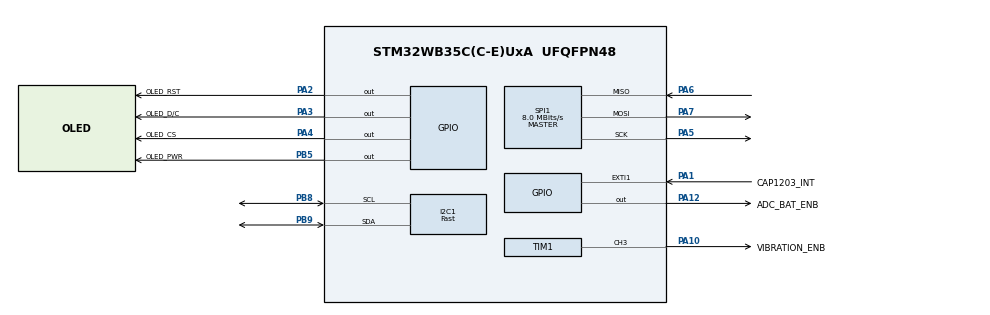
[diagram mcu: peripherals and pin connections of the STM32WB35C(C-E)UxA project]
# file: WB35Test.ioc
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I2C1.I2C_Speed_Mode=I2C_Fast
I2C1.Timing=0x00300F38
Mcu.Family=STM32WB
Mcu.Name=STM32WB35C(C-E)UxA
Mcu.Package=UFQFPN48
NVIC.EXTI1_IRQn=true\:0\:0\:false\:false\:true\:true\:true
NVIC.HSEM_IRQn=true\:0\:0\:false\:false\:true\:false\:true
NVIC.IPCC_C1_RX_IRQn=true\:0\:0\:false\:false\:true\:true\:true
NVIC.IPCC_C1_TX_IRQn=true\:0\:0\:false\:false\:true\:true\:true
NVIC.PriorityGroup=NVIC_PRIORITYGROUP_4
NVIC.RTC_WKUP_IRQn=true\:0\:0\:false\:false\:true\:true\:true
NVIC.TIM1_UP_TIM16_IRQn=true\:0\:0\:false\:false\:true\:true\:true
OSC_IN.Mode=HSE-External-Oscillator
OSC_IN.Signal=RCC_OSC_IN
OSC_OUT.Mode=HSE-External-Oscillator
OSC_OUT.Signal=RCC_OSC_OUT
PA0.Mode=SYS_WakeUp0
PA0.Signal=SYS_WKUP1
PA1.GPIO_Label=CAP1203_INT
PA1.Signal=GPXTI1
PA10.GPIO_Label=VIBRATION_ENB
PA10.Signal=S_TIM1_CH3
PA12.GPIO_Label=ADC_BAT_ENB
PA12.PinState=GPIO_PIN_SET
PA12.Signal=GPIO_Output
PA2.GPIO_Label=OLED_RST
PA2.Signal=GPIO_Output
PA3.GPIO_Label=OLED_D/C
PA3.Signal=GPIO_Output
PA4.GPIO_Label=OLED_CS
PA4.PinState=GPIO_PIN_SET
PA4.Signal=GPIO_Output
PA5.Mode=Full_Duplex_Master
PA5.Signal=SPI1_SCK
PA6.Mode=Full_Duplex_Master
PA6.Signal=SPI1_MISO
PA7.Mode=Full_Duplex_Master
PA7.Signal=SPI1_MOSI
PB5.GPIO_Label=OLED_PWR
PB5.Signal=GPIO_Output
PB8.Mode=I2C
PB8.Signal=I2C1_SCL
PB9.Mode=I2C
PB9.Signal=I2C1_SDA
PC14-OSC32_IN.Mode=LSE-External-Oscillator
PC14-OSC32_IN.Signal=RCC_OSC32_IN
PC15-OSC32_OUT.Mode=LSE-External-Oscillator
PC15-OSC32_OUT.Signal=RCC_OSC32_OUT
ProjectManager.HeapSize=0x200
ProjectManager.StackSize=0x400
ProjectManager.TargetToolchain=MDK-ARM V5.32
RCC.ADCFreq_Value=128000000
RCC.AHBFreq_Value=32000000
RCC.APB1Freq_Value=32000000
RCC.APB1TimFreq_Value=32000000
RCC.APB2Freq_Value=32000000
RCC.APB2TimFreq_Value=32000000
RCC.APB3Freq_Value=16000000
RCC.CodegenConfigPeriph=true
RCC.CortexFreq_Value=32000000
RCC.HCLKFreq_Value=32000000
RCC.HSE_VALUE=32000000
RCC.HSI48_VALUE=48000000
RCC.HSI_VALUE=16000000
RCC.LSE_Timout=5000
RCC.MSIClockRange=RCC_MSIRANGE_10
RCC.RFWKPClockSelection=RCC_RFWKPCLKSOURCE_LSE
RCC.RTCClockSelection=RCC_RTCCLKSOURCE_LSE
RCC.SYSCLKFreq_VALUE=32000000
RCC.USBFreq_Value=128000000
RCC.VCOOutputFreq_Value=256000000
RF1.Mode=RF1_Activate
RF1.Signal=RF_RF1
SH.S_TIM1_CH3.0=TIM1_CH3,PWM Generation3 CH3
SPI1.BaudRatePrescaler=SPI_BAUDRATEPRESCALER_4
SPI1.CalculateBaudRate=8.0 MBits/s
SPI1.DataSize=SPI_DATASIZE_8BIT
SPI1.Direction=SPI_DIRECTION_2LINES
SPI1.Mode=SPI_MODE_MASTER
SPI1.VirtualType=VM_MASTER
STM32_WPAN.AD_TYPE_COMPLETE_LOCAL_NAME=SMRT_GLASS
STM32_WPAN.AD_TYPE_COMPLETE_LOCAL_NAME_LENGTH=11
STM32_WPAN.CUSTOM_P2P_SERVER=Disabled
STM32_WPAN.CUSTOM_TEMPLATE=Enabled
STM32_WPAN.GAP_PERIPHERAL_ROLE=0
STM32_WPAN.INCLUDE_AD_TYPE_COMPLETE_LOCAL_NAME=1
STM32_WPAN.LOCAL_NAME=MY_GLAS
STM32_WPAN.LOCAL_NAME_FORMATTED=,'M','Y','_','G','L','A','S'
STM32_WPAN.NUMBER_OF_SERVICES=2
STM32_WPAN.SERVICE1_CHAR1_GATT_NOTIFY_ATTRIBUTE_WRITE=\ 
STM32_WPAN.SERVICE1_CHAR1_GATT_NOTIFY_READ_REQ_AND_WAIT_FOR_APPL_RESP=\ 
STM32_WPAN.SERVICE1_CHAR1_GATT_NOTIFY_WRITE_REQ_AND_WAIT_FOR_APPL_RESP=\ 
STM32_WPAN.SERVICE1_CHAR1_LONG_NAME=DVC_FW_NR
STM32_WPAN.SERVICE1_CHAR1_PROP_READ=CHAR_PROP_READ
STM32_WPAN.SERVICE1_CHAR1_SHORT_NAME=DVC_FW_NR
STM32_WPAN.SERVICE1_CHAR1_UUID=00 11
STM32_WPAN.SERVICE1_CHAR1_VALUE_LENGTH=4
STM32_WPAN.SERVICE1_CHAR2_GATT_NOTIFY_ATTRIBUTE_WRITE=\ 
STM32_WPAN.SERVICE1_CHAR2_GATT_NOTIFY_READ_REQ_AND_WAIT_FOR_APPL_RESP=\ 
STM32_WPAN.SERVICE1_CHAR2_GATT_NOTIFY_WRITE_REQ_AND_WAIT_FOR_APPL_RESP=\ 
STM32_WPAN.SERVICE1_CHAR2_LENGTH_CHARACTERISTIC=CHAR_VALUE_LEN_VARIABLE
STM32_WPAN.SERVICE1_CHAR2_LONG_NAME=DVC_NAME
STM32_WPAN.SERVICE1_CHAR2_PROP_READ=CHAR_PROP_READ
STM32_WPAN.SERVICE1_CHAR2_SHORT_NAME=DVC_NAME
STM32_WPAN.SERVICE1_CHAR2_UUID=00 12
STM32_WPAN.SERVICE1_CHAR2_VALUE_LENGTH=32
STM32_WPAN.SERVICE1_LONG_NAME=DVC_INFO_SVC
STM32_WPAN.SERVICE1_NUMBER_OF_CHARACTERISTICS=2
STM32_WPAN.SERVICE1_SHORT_NAME=DVC_INFO_SVC
STM32_WPAN.SERVICE1_UUID=00 10
STM32_WPAN.SERVICE2_CHAR1_LENGTH_CHARACTERISTIC=CHAR_VALUE_LEN_VARIABLE
STM32_WPAN.SERVICE2_CHAR1_LONG_NAME=TIME_UPDATE
STM32_WPAN.SERVICE2_CHAR1_PROP_WRITE_WITHOUT_RESP=CHAR_PROP_WRITE_WITHOUT_RESP
STM32_WPAN.SERVICE2_CHAR1_SHORT_NAME=TIME_UPDATE
STM32_WPAN.SERVICE2_CHAR1_UUID=00 21
STM32_WPAN.SERVICE2_CHAR1_VALUE_LENGTH=32
STM32_WPAN.SERVICE2_CHAR2_GATT_NOTIFY_READ_REQ_AND_WAIT_FOR_APPL_RESP=GATT_NOTIFY_READ_REQ_AND_WAIT_FOR_APPL_RESP
STM32_WPAN.SERVICE2_CHAR2_GATT_NOTIFY_WRITE_REQ_AND_WAIT_FOR_APPL_RESP=GATT_NOTIFY_WRITE_REQ_AND_WAIT_FOR_APPL_RESP
STM32_WPAN.SERVICE2_CHAR2_LENGTH_CHARACTERISTIC=CHAR_VALUE_LEN_VARIABLE
STM32_WPAN.SERVICE2_CHAR2_LONG_NAME=PUSH_NOTIFICATION
STM32_WPAN.SERVICE2_CHAR2_PROP_WRITE_WITHOUT_RESP=CHAR_PROP_WRITE_WITHOUT_RESP
STM32_WPAN.SERVICE2_CHAR2_SHORT_NAME=PUSH_NOTIFICATION
STM32_WPAN.SERVICE2_CHAR2_UUID=00 22
STM32_WPAN.SERVICE2_CHAR2_VALUE_LENGTH=128
STM32_WPAN.SERVICE2_LONG_NAME=RECEIVE_SVC
STM32_WPAN.SERVICE2_NUMBER_OF_CHARACTERISTICS=2
STM32_WPAN.SERVICE2_SHORT_NAME=RECEIVE_SVC
STM32_WPAN.SERVICE2_UUID=00 20
TIM1.Channel-PWM\ Generation3\ CH3=TIM_CHANNEL_3
TIM1.Period=99
TIM1.Prescaler=3
TIM1.TIM_MasterOutputTrigger=TIM_TRGO_UPDATE
TIM1.TIM_MasterOutputTrigger2=TIM_TRGO2_UPDATE
VP_HSEM_VS_HSEM.Mode=HSEM_Activate
VP_IPCC_VS_IPCC.Mode=IPCC_Activate
VP_RTC_VS_RTC_Activate.Mode=RTC_Enabled
VP_RTC_VS_RTC_WakeUp_intern.Mode=WakeUp
VP_SEQUENCER_VS_SEQUENCER.Mode=SEQUENCER_Enabled
VP_STM32_WPAN_VS_BLE_HOST.Mode=STM32_WPAN_Enabled
VP_TIM1_VS_ClockSourceINT.Mode=Internal
VP_TINY_LPM_VS_TINY_LPM.Mode=TINY_LPM_Enabled
board=custom

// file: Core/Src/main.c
/* USER CODE BEGIN Header */
/**
  ******************************************************************************
  * @file           : main.c
  * @brief          : Main program body
  ******************************************************************************
  * @attention
  *
  * Copyright (c) 2022 STMicroelectronics.
  * All rights reserved.
  *
  * This software is licensed under terms that can be found in the LICENSE file
  * in the root directory of this software component.
  * If no LICENSE file comes with this software, it is provided AS-IS.
  *
  ******************************************************************************
  */
/* USER CODE END Header */
#include "main.h"

/* USER CODE BEGIN Includes */
#include "glasses_app.h"
#include "glasses_ota.h"
#include "app_ble.h"
/* USER CODE END Includes */

I2C_HandleTypeDef hi2c1;

IPCC_HandleTypeDef hipcc;

RTC_HandleTypeDef hrtc;

SPI_HandleTypeDef hspi1;

TIM_HandleTypeDef htim1;

void SystemClock_Config(void);
void PeriphCommonClock_Config(void);
static void MX_IPCC_Init(void);
static void MX_GPIO_Init(void);
static void MX_RTC_Init(void);
static void MX_RF_Init(void);
static void MX_I2C1_Init(void);
static void MX_SPI1_Init(void);
static void MX_TIM1_Init(void);

int main(void)
{

  /* MCU Configuration--------------------------------------------------------*/

  /* Reset of all peripherals, Initializes the Flash interface and the Systick. */
  HAL_Init();
  /* Config code for STM32_WPAN (HSE Tuning must be done before system clock configuration) */
  MX_APPE_Config();

  /* USER CODE BEGIN Init */
  Glasses_WatchdogInit();
/* USER CODE END Init */

  /* Configure the system clock */
  SystemClock_Config();

/* Configure the peripherals common clocks */
  PeriphCommonClock_Config();

  /* IPCC initialisation */
   MX_IPCC_Init();

  /* Initialize all configured peripherals */
  MX_GPIO_Init();
  MX_RTC_Init();
  MX_RF_Init();
  MX_I2C1_Init();
  MX_SPI1_Init();
  MX_TIM1_Init();
  /* USER CODE BEGIN 2 */
#ifdef SMARTGLASSES_BOOTLOADER
  Glasses_BootTryApplication();
#endif
  Glasses_Init();
/* USER CODE END 2 */

  /* Init code for STM32_WPAN */
  MX_APPE_Init();
  /* Infinite loop */
  while (1)
  {
    MX_APPE_Process();

    /* USER CODE BEGIN 3 */
    APP_BLE_Process();
    Glasses_Process();
    Glasses_OtaProcess();
    __WFI(); /* CPU1 sleep at the existing clock; CPU2 continues BLE. SysTick stays on. */
  }
/* USER CODE END 3 */
}

void SystemClock_Config(void)
{
  RCC_OscInitTypeDef RCC_OscInitStruct = {0};
  RCC_ClkInitTypeDef RCC_ClkInitStruct = {0};

  /** Configure LSE Drive Capability
  */
  HAL_PWR_EnableBkUpAccess();
  __HAL_RCC_LSEDRIVE_CONFIG(RCC_LSEDRIVE_LOW);
  /** Configure the main internal regulator output voltage
  */
  __HAL_PWR_VOLTAGESCALING_CONFIG(PWR_REGULATOR_VOLTAGE_SCALE1);
  /** Initializes the RCC Oscillators according to the specified parameters
  * in the RCC_OscInitTypeDef structure.
  */
  RCC_OscInitStruct.OscillatorType = RCC_OSCILLATORTYPE_HSI|RCC_OSCILLATORTYPE_HSE
                              |RCC_OSCILLATORTYPE_LSE|RCC_OSCILLATORTYPE_MSI;
  RCC_OscInitStruct.HSEState = RCC_HSE_ON;
  RCC_OscInitStruct.LSEState = RCC_LSE_ON;
  RCC_OscInitStruct.HSIState = RCC_HSI_ON;
  RCC_OscInitStruct.MSIState = RCC_MSI_ON;
  RCC_OscInitStruct.HSICalibrationValue = RCC_HSICALIBRATION_DEFAULT;
  RCC_OscInitStruct.MSICalibrationValue = RCC_MSICALIBRATION_DEFAULT;
  RCC_OscInitStruct.MSIClockRange = RCC_MSIRANGE_10;
  RCC_OscInitStruct.PLL.PLLState = RCC_PLL_NONE;
  if (HAL_RCC_OscConfig(&RCC_OscInitStruct) != HAL_OK)
  {
    Error_Handler();
  }
  /** Configure the SYSCLKSource, HCLK, PCLK1 and PCLK2 clocks dividers
  */
  RCC_ClkInitStruct.ClockType = RCC_CLOCKTYPE_HCLK4|RCC_CLOCKTYPE_HCLK2
                              |RCC_CLOCKTYPE_HCLK|RCC_CLOCKTYPE_SYSCLK
                              |RCC_CLOCKTYPE_PCLK1|RCC_CLOCKTYPE_PCLK2;
  RCC_ClkInitStruct.SYSCLKSource = RCC_SYSCLKSOURCE_MSI;
  RCC_ClkInitStruct.AHBCLKDivider = RCC_SYSCLK_DIV1;
  RCC_ClkInitStruct.APB1CLKDivider = RCC_HCLK_DIV1;
  RCC_ClkInitStruct.APB2CLKDivider = RCC_HCLK_DIV1;
  RCC_ClkInitStruct.AHBCLK2Divider = RCC_SYSCLK_DIV1;
  RCC_ClkInitStruct.AHBCLK4Divider = RCC_SYSCLK_DIV1;

  if (HAL_RCC_ClockConfig(&RCC_ClkInitStruct, FLASH_LATENCY_1) != HAL_OK)
  {
    Error_Handler();
  }
}

void PeriphCommonClock_Config(void)
{
  RCC_PeriphCLKInitTypeDef PeriphClkInitStruct = {0};

  /** Initializes the peripherals clock
  */
  PeriphClkInitStruct.PeriphClockSelection = RCC_PERIPHCLK_SMPS|RCC_PERIPHCLK_RFWAKEUP;
  PeriphClkInitStruct.RFWakeUpClockSelection = RCC_RFWKPCLKSOURCE_LSE;
  PeriphClkInitStruct.SmpsClockSelection = RCC_SMPSCLKSOURCE_HSI;
  PeriphClkInitStruct.SmpsDivSelection = RCC_SMPSCLKDIV_RANGE1;

  if (HAL_RCCEx_PeriphCLKConfig(&PeriphClkInitStruct) != HAL_OK)
  {
    Error_Handler();
  }
}

static void MX_I2C1_Init(void)
{

  hi2c1.Instance = I2C1;
  hi2c1.Init.Timing = 0x00300F38;
  hi2c1.Init.OwnAddress1 = 0;
  hi2c1.Init.AddressingMode = I2C_ADDRESSINGMODE_7BIT;
  hi2c1.Init.DualAddressMode = I2C_DUALADDRESS_DISABLE;
  hi2c1.Init.OwnAddress2 = 0;
  hi2c1.Init.OwnAddress2Masks = I2C_OA2_NOMASK;
  hi2c1.Init.GeneralCallMode = I2C_GENERALCALL_DISABLE;
  hi2c1.Init.NoStretchMode = I2C_NOSTRETCH_DISABLE;
  if (HAL_I2C_Init(&hi2c1) != HAL_OK)
  {
    Error_Handler();
  }
  /** Configure Analogue filter
  */
  if (HAL_I2CEx_ConfigAnalogFilter(&hi2c1, I2C_ANALOGFILTER_ENABLE) != HAL_OK)
  {
    Error_Handler();
  }
  /** Configure Digital filter
  */
  if (HAL_I2CEx_ConfigDigitalFilter(&hi2c1, 0) != HAL_OK)
  {
    Error_Handler();
  }

}

static void MX_IPCC_Init(void)
{

  hipcc.Instance = IPCC;
  if (HAL_IPCC_Init(&hipcc) != HAL_OK)
  {
    Error_Handler();
  }

}

static void MX_RF_Init(void)
{

}

static void MX_RTC_Init(void)
{

  /** Initialize RTC Only
  */
  hrtc.Instance = RTC;
  hrtc.Init.HourFormat = RTC_HOURFORMAT_24;
  hrtc.Init.AsynchPrediv = CFG_RTC_ASYNCH_PRESCALER;
  hrtc.Init.SynchPrediv = CFG_RTC_SYNCH_PRESCALER;
  hrtc.Init.OutPut = RTC_OUTPUT_DISABLE;
  hrtc.Init.OutPutPolarity = RTC_OUTPUT_POLARITY_HIGH;
  hrtc.Init.OutPutType = RTC_OUTPUT_TYPE_OPENDRAIN;
  hrtc.Init.OutPutRemap = RTC_OUTPUT_REMAP_NONE;
  if (HAL_RTC_Init(&hrtc) != HAL_OK)
  {
    Error_Handler();
  }
  /* The ST timer server owns WUTE; do not start interrupts before HW_TS_Init. */

}

static void MX_SPI1_Init(void)
{

  /* SPI1 parameter configuration*/
  hspi1.Instance = SPI1;
  hspi1.Init.Mode = SPI_MODE_MASTER;
  hspi1.Init.Direction = SPI_DIRECTION_2LINES;
  hspi1.Init.DataSize = SPI_DATASIZE_8BIT;
  hspi1.Init.CLKPolarity = SPI_POLARITY_LOW;
  hspi1.Init.CLKPhase = SPI_PHASE_1EDGE;
  hspi1.Init.NSS = SPI_NSS_SOFT;
  hspi1.Init.BaudRatePrescaler = SPI_BAUDRATEPRESCALER_4;
  hspi1.Init.FirstBit = SPI_FIRSTBIT_MSB;
  hspi1.Init.TIMode = SPI_TIMODE_DISABLE;
  hspi1.Init.CRCCalculation = SPI_CRCCALCULATION_DISABLE;
  hspi1.Init.CRCPolynomial = 7;
  hspi1.Init.CRCLength = SPI_CRC_LENGTH_DATASIZE;
  hspi1.Init.NSSPMode = SPI_NSS_PULSE_ENABLE;
  if (HAL_SPI_Init(&hspi1) != HAL_OK)
  {
    Error_Handler();
  }

}

static void MX_TIM1_Init(void)
{

  TIM_ClockConfigTypeDef sClockSourceConfig = {0};
  TIM_MasterConfigTypeDef sMasterConfig = {0};
  TIM_OC_InitTypeDef sConfigOC = {0};
  TIM_BreakDeadTimeConfigTypeDef sBreakDeadTimeConfig = {0};

  htim1.Instance = TIM1;
  htim1.Init.Prescaler = 3;
  htim1.Init.CounterMode = TIM_COUNTERMODE_UP;
  htim1.Init.Period = 99;
  htim1.Init.ClockDivision = TIM_CLOCKDIVISION_DIV1;
  htim1.Init.RepetitionCounter = 0;
  htim1.Init.AutoReloadPreload = TIM_AUTORELOAD_PRELOAD_DISABLE;
  if (HAL_TIM_Base_Init(&htim1) != HAL_OK)
  {
    Error_Handler();
  }
  sClockSourceConfig.ClockSource = TIM_CLOCKSOURCE_INTERNAL;
  if (HAL_TIM_ConfigClockSource(&htim1, &sClockSourceConfig) != HAL_OK)
  {
    Error_Handler();
  }
  if (HAL_TIM_PWM_Init(&htim1) != HAL_OK)
  {
    Error_Handler();
  }
  sMasterConfig.MasterOutputTrigger = TIM_TRGO_UPDATE;
  sMasterConfig.MasterOutputTrigger2 = TIM_TRGO2_UPDATE;
  sMasterConfig.MasterSlaveMode = TIM_MASTERSLAVEMODE_DISABLE;
  if (HAL_TIMEx_MasterConfigSynchronization(&htim1, &sMasterConfig) != HAL_OK)
  {
    Error_Handler();
  }
  sConfigOC.OCMode = TIM_OCMODE_PWM1;
  sConfigOC.Pulse = 0;
  sConfigOC.OCPolarity = TIM_OCPOLARITY_HIGH;
  sConfigOC.OCNPolarity = TIM_OCNPOLARITY_HIGH;
  sConfigOC.OCFastMode = TIM_OCFAST_DISABLE;
  sConfigOC.OCIdleState = TIM_OCIDLESTATE_RESET;
  sConfigOC.OCNIdleState = TIM_OCNIDLESTATE_RESET;
  if (HAL_TIM_PWM_ConfigChannel(&htim1, &sConfigOC, TIM_CHANNEL_3) != HAL_OK)
  {
    Error_Handler();
  }
  sBreakDeadTimeConfig.OffStateRunMode = TIM_OSSR_DISABLE;
  sBreakDeadTimeConfig.OffStateIDLEMode = TIM_OSSI_DISABLE;
  sBreakDeadTimeConfig.LockLevel = TIM_LOCKLEVEL_OFF;
  sBreakDeadTimeConfig.DeadTime = 0;
  sBreakDeadTimeConfig.BreakState = TIM_BREAK_DISABLE;
  sBreakDeadTimeConfig.BreakPolarity = TIM_BREAKPOLARITY_HIGH;
  sBreakDeadTimeConfig.BreakFilter = 0;
  sBreakDeadTimeConfig.BreakAFMode = TIM_BREAK_AFMODE_INPUT;
  sBreakDeadTimeConfig.Break2State = TIM_BREAK2_DISABLE;
  sBreakDeadTimeConfig.Break2Polarity = TIM_BREAK2POLARITY_HIGH;
  sBreakDeadTimeConfig.Break2Filter = 0;
  sBreakDeadTimeConfig.Break2AFMode = TIM_BREAK_AFMODE_INPUT;
  sBreakDeadTimeConfig.AutomaticOutput = TIM_AUTOMATICOUTPUT_DISABLE;
  if (HAL_TIMEx_ConfigBreakDeadTime(&htim1, &sBreakDeadTimeConfig) != HAL_OK)
  {
    Error_Handler();
  }
  HAL_TIM_MspPostInit(&htim1);

}

static void MX_GPIO_Init(void)
{
  GPIO_InitTypeDef GPIO_InitStruct = {0};

  /* GPIO Ports Clock Enable */
  __HAL_RCC_GPIOC_CLK_ENABLE();
  __HAL_RCC_GPIOB_CLK_ENABLE();
  __HAL_RCC_GPIOA_CLK_ENABLE();

  /*Configure GPIO pin Output Level */
  HAL_GPIO_WritePin(GPIOA, OLED_RST_Pin|OLED_D_C_Pin, GPIO_PIN_RESET);

  /*Configure GPIO pin Output Level */
  HAL_GPIO_WritePin(GPIOA, OLED_CS_Pin|ADC_BAT_ENB_Pin, GPIO_PIN_SET);

  /*Configure GPIO pin Output Level */
  HAL_GPIO_WritePin(OLED_PWR_GPIO_Port, OLED_PWR_Pin, GPIO_PIN_RESET);

  /*Configure GPIO pin : CAP1203_INT_Pin */
  GPIO_InitStruct.Pin = CAP1203_INT_Pin;
  GPIO_InitStruct.Mode = GPIO_MODE_IT_FALLING;
  GPIO_InitStruct.Pull = GPIO_NOPULL;
  HAL_GPIO_Init(CAP1203_INT_GPIO_Port, &GPIO_InitStruct);

  /*Configure GPIO pins : OLED_RST_Pin OLED_D_C_Pin OLED_CS_Pin ADC_BAT_ENB_Pin */
  GPIO_InitStruct.Pin = OLED_RST_Pin|OLED_D_C_Pin|OLED_CS_Pin|ADC_BAT_ENB_Pin;
  GPIO_InitStruct.Mode = GPIO_MODE_OUTPUT_PP;
  GPIO_InitStruct.Pull = GPIO_NOPULL;
  GPIO_InitStruct.Speed = GPIO_SPEED_FREQ_LOW;
  HAL_GPIO_Init(GPIOA, &GPIO_InitStruct);

  /*Configure GPIO pin : OLED_PWR_Pin */
  GPIO_InitStruct.Pin = OLED_PWR_Pin;
  GPIO_InitStruct.Mode = GPIO_MODE_OUTPUT_PP;
  GPIO_InitStruct.Pull = GPIO_NOPULL;
  GPIO_InitStruct.Speed = GPIO_SPEED_FREQ_LOW;
  HAL_GPIO_Init(OLED_PWR_GPIO_Port, &GPIO_InitStruct);

  /* EXTI interrupt init*/
  HAL_NVIC_SetPriority(EXTI1_IRQn, 0, 0);
  HAL_NVIC_EnableIRQ(EXTI1_IRQn);

}

void Error_Handler(void)
{
  /* USER CODE BEGIN Error_Handler_Debug */
  Glasses_Fatal(1);
/* USER CODE END Error_Handler_Debug */
}
